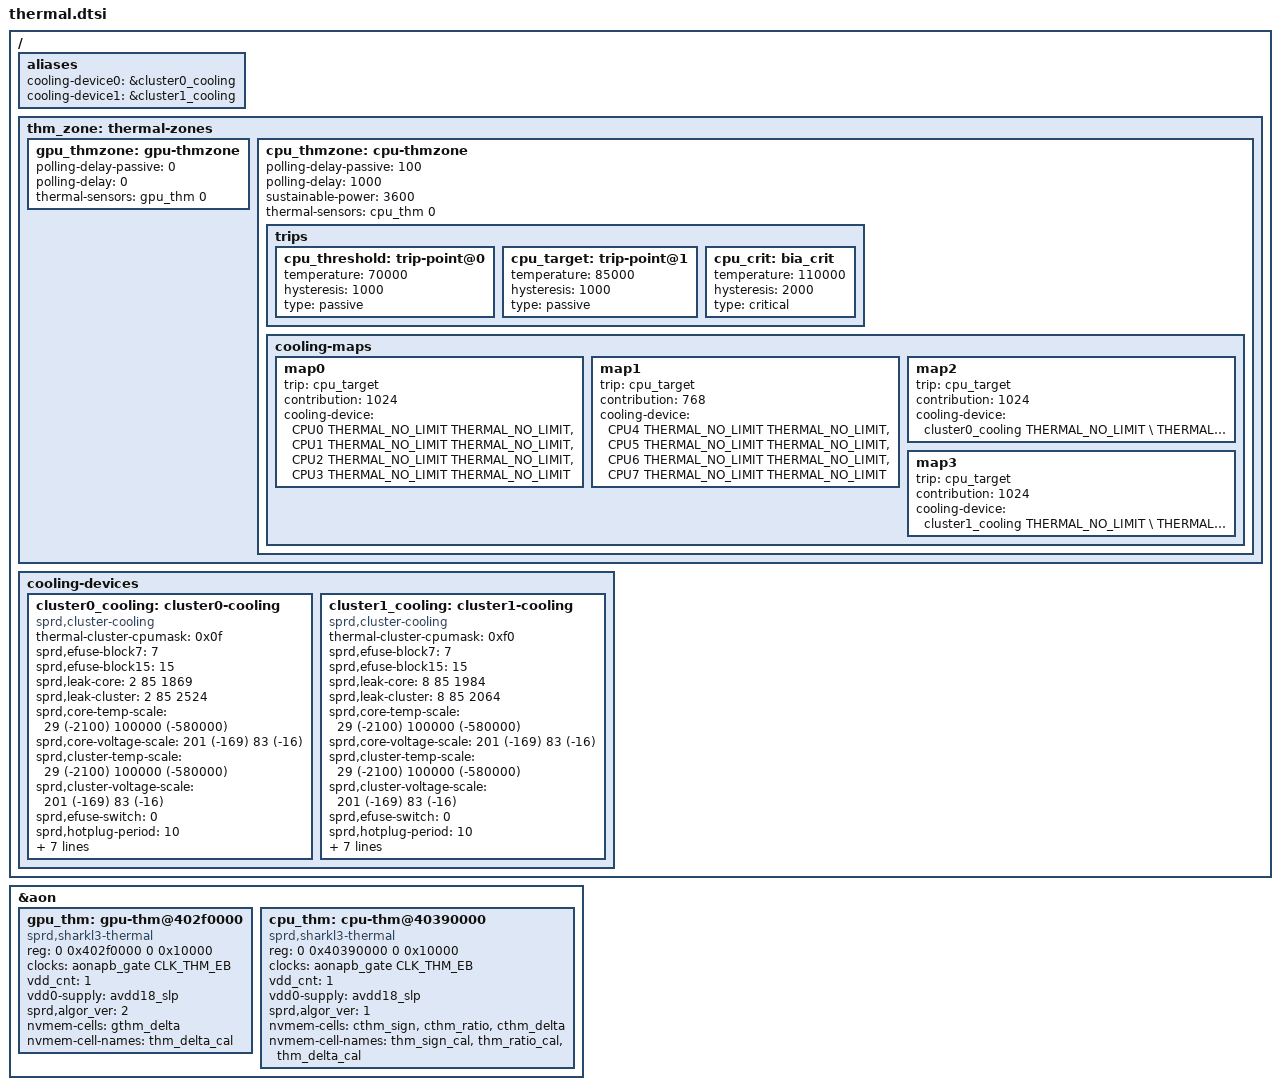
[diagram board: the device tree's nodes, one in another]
// SPDX-License-Identifier: (GPL-2.0+ OR MIT)
/*
 * Unisoc THERMAL dts file
 *
 * Copyright (C) 2020, Unisoc Inc.
 *
 */
#include <dt-bindings/thermal/thermal.h>

&aon {
	gpu_thm: gpu-thm@402f0000 {
		compatible = "sprd,sharkl3-thermal";
		reg = <0 0x402f0000 0 0x10000>;
		clock-names = "enable";
		clocks = <&aonapb_gate CLK_THM_EB>;
		#thermal-sensor-cells = <1>;
		vdd_cnt = <1>;
		vdd0-supply = <&avdd18_slp>;
		sprd,algor_ver = <2>;
		nvmem-cells = <&gthm_delta>;
		nvmem-cell-names = "thm_delta_cal";
	};

	cpu_thm: cpu-thm@40390000 {
		compatible = "sprd,sharkl3-thermal";
		reg = <0 0x40390000 0 0x10000>;
		clock-names = "enable";
		clocks = <&aonapb_gate CLK_THM_EB>;
		#thermal-sensor-cells = <1>;
		vdd_cnt = <1>;
		vdd0-supply = <&avdd18_slp>;
		sprd,algor_ver = <1>;
		nvmem-cells = <&cthm_sign>, <&cthm_ratio>, <&cthm_delta>;
		nvmem-cell-names = "thm_sign_cal", "thm_ratio_cal", "thm_delta_cal";
	};

};

/ {
	aliases {
		cooling-device0 = &cluster0_cooling;
		cooling-device1 = &cluster1_cooling;
	};

	thm_zone: thermal-zones {
		gpu_thmzone: gpu-thmzone {
			polling-delay-passive = <0>;
			polling-delay = <0>;
			thermal-sensors = <&gpu_thm  0>;
		};

		cpu_thmzone: cpu-thmzone {
			polling-delay-passive = <100>;
			polling-delay = <1000>;
			sustainable-power = <3600>;
			thermal-sensors = <&cpu_thm  0>;
			trips {
				cpu_threshold: trip-point@0 {
					temperature = <70000>;
					hysteresis = <1000>;
					type = "passive";
				};
				cpu_target: trip-point@1 {
					temperature = <85000>;
					hysteresis = <1000>;
					type = "passive";
				};
				cpu_crit: bia_crit {
					temperature = <110000>;
					hysteresis = <2000>;
					type = "critical";
				};
			};
			cooling-maps {
				map0 {
					trip = <&cpu_target>;
					contribution = <1024>;
					cooling-device =
					<&CPU0 THERMAL_NO_LIMIT THERMAL_NO_LIMIT>,
					<&CPU1 THERMAL_NO_LIMIT THERMAL_NO_LIMIT>,
					<&CPU2 THERMAL_NO_LIMIT THERMAL_NO_LIMIT>,
					<&CPU3 THERMAL_NO_LIMIT THERMAL_NO_LIMIT>;
				};
				map1 {
					trip = <&cpu_target>;
					contribution = <768>;
					cooling-device =
					<&CPU4 THERMAL_NO_LIMIT THERMAL_NO_LIMIT>,
					<&CPU5 THERMAL_NO_LIMIT THERMAL_NO_LIMIT>,
					<&CPU6 THERMAL_NO_LIMIT THERMAL_NO_LIMIT>,
					<&CPU7 THERMAL_NO_LIMIT THERMAL_NO_LIMIT>;
				};
				map2 {
					trip = <&cpu_target>;
					contribution = <1024>;
					cooling-device =
					<&cluster0_cooling THERMAL_NO_LIMIT \
					THERMAL_NO_LIMIT>;
				};
				map3 {
					trip = <&cpu_target>;
					contribution = <1024>;
					cooling-device =
					<&cluster1_cooling THERMAL_NO_LIMIT \
					THERMAL_NO_LIMIT>;
				};
			};
		};
	};

	cooling-devices {
		cluster0_cooling: cluster0-cooling {
			compatible = "sprd,cluster-cooling";
			thermal-cluster-cpumask = <0x0f>;
			#cooling-cells = <2>; /* min followed by max */
			sprd,efuse-block7 = <7>;
			sprd,efuse-block15 = <15>;
			/* core_leak =                             */
			/*(LIT_LEAK[4:0]+1) x 2mA x 0.85V x 18.69% */
			sprd,leak-core = <2 85 1869>;
			/* cluster_leak =                           */
			/* (LIT_LEAK[4:0]+1) x 2mA x 0.85V x 25.24% */
			sprd,leak-cluster = <2 85 2524>;
			/*core Tscale = aT^3 + bT^2 + cT +di   */
			sprd,core-temp-scale =
			/* a*10^7   b*10^7      c*10^7     d*10^7 */
			<  29      (-2100)      100000    (-580000)>;
			/*core Vscale = eV^3 + fV^2 + gV + h */
			sprd,core-voltage-scale =
			/* e*10^2   f*10^2     g*10^2  h*10^2*/
			<  201     (-169)      83      (-16)>;
			/*cluster Tscale = aT^3 + bT^2 + cT +di   */
			sprd,cluster-temp-scale =
			/* a*10^7   b*10^7      c*10^7     d*10^7 */
			<  29      (-2100)      100000    (-580000)>;
			/*cluster Vscale = eV^3 + fV^2 + gV + h */
			sprd,cluster-voltage-scale =
			/* e*10^2   f*10^2     g*10^2  h*10^2*/
			<  201     (-169)      83      (-16)>;
			sprd,efuse-switch = <0>;
			sprd,hotplug-period = <10>;
			sprd,min-cpufreq = <768000>;
			sprd,min-cpunum = <4>;
			sprd,max-temp = <90000>;
			sprd,core-base = <2400>;
			sprd,cluster-base = <3970>;
			sprd,dynamic-core =
			/*Pdynperghz*10    Freq     Vbase  */
			< 1007           1000     1000>;
			sprd,dynamic-cluster =
			/*Pdynperghz*10    Freq     Vbase  */
			< 747           1000     1000>;
		};
		cluster1_cooling: cluster1-cooling {
			compatible = "sprd,cluster-cooling";
			thermal-cluster-cpumask = <0xf0>;
			#cooling-cells = <2>; /* min followed by max */
			sprd,efuse-block7 = <7>;
			sprd,efuse-block15 = <15>;
			/* core_leak =                             */
			/*(LIT_LEAK[4:0]+1) x 2mA x 0.85V x 18.69% */
			sprd,leak-core = <8 85 1984>;
			/* cluster_leak =                           */
			/* (LIT_LEAK[4:0]+1) x 2mA x 0.85V x 25.24% */
			sprd,leak-cluster = <8 85 2064>;
			/*core Tscale = aT^3 + bT^2 + cT +d  */
			sprd,core-temp-scale =
			/* a*10^7   b*10^7	c*10^7	   d*10^7*/
			<  29      (-2100)      100000    (-580000)>;
			/* core  Vscale = eV^3 + fV^2 + gV + h */
			sprd,core-voltage-scale =
			/* e*10^2  f*10^2     g*10^2  h*10^2*/
			<  201     (-169)      83      (-16)>;
			/*cluster Tscale = aT^3 + bT^2 + cT +di   */
			sprd,cluster-temp-scale =
			/* a*10^7   b*10^7      c*10^7     d*10^7 */
			<  29      (-2100)      100000    (-580000)>;
			/*cluster Vscale = eV^3 + fV^2 + gV + h */
			sprd,cluster-voltage-scale =
			/* e*10^2   f*10^2     g*10^2  h*10^2*/
			<  201     (-169)      83      (-16)>;
			sprd,efuse-switch = <0>;
			sprd,hotplug-period = <10>;
			sprd,min-cpufreq = <768000>;
			sprd,min-cpunum = <0>;
			sprd,max-temp = <85000>;
			sprd,core-base = <4190>;
			sprd,cluster-base = <3970>;
			sprd,dynamic-core =
			/* Pdynperghz*10    Freq     Vbase */
			<  1536          1000     1000>;
			sprd,dynamic-cluster =
			/* Pdynperghz*10    Freq     Vbase */
			<  747            1000     1000>;
		};
	};
};

